# ATmega645P device description
Architecture: AVR8; Family: megaAVR
Registers are 8-bit, access not given, no defined reset value unless marked. A register's access mark holds for its fields unless they carry their own. Offsets are from the block's base; [hi:lo] are bit positions.

## JTAG — JTAG Interface
Instances: JTAG 0x00
0x51 OCDR — On-Chip Debug Related Register in I/O Memory
0x54 MCUSR — MCU Status Register
  [4] JTRF — JTAG Reset Flag
0x55 MCUCR — MCU Control Register
  [7] JTD — JTAG Interface Disable

## EXINT — External Interrupts
Instances: EXINT 0x00
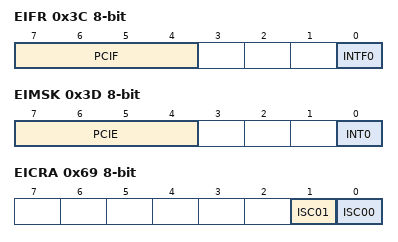
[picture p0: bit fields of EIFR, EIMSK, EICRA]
0x3C EIFR — External Interrupt Flag Register
  [7:4] PCIF — Pin Change Interrupt Flags
  [0] INTF0 — External Interrupt Flag 0
0x3D EIMSK — External Interrupt Mask Register
  [7:4] PCIE — Pin Change Interrupt Enables
  [0] INT0 — External Interrupt Request 0 Enable
0x69 EICRA — External Interrupt Control Register A
  [1] ISC01 — External Interrupt Sense Control 0 Bit 1
  [0] ISC00 — External Interrupt Sense Control 0 Bit 0
    0=Low Level of INTX; 1=Any Logical Change of INTX; 2=Falling Edge of INTX; 3=Rising Edge of INTX
0x6B PCMSK0 — Pin Change Mask Register 0
0x6C PCMSK1 — Pin Change Mask Register 1

## EEPROM
Instances: EEPROM 0x00
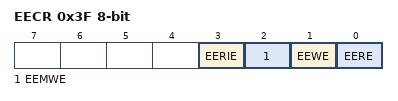
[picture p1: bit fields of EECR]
0x3F EECR — EEPROM Control Register
  [3] EERIE — EEPROM Ready Interrupt Enable
  [2] EEMWE — EEPROM Master Write Enable
  [1] EEWE — EEPROM Write Enable
  [0] EERE — EEPROM Read Enable
0x40 EEDR — EEPROM Data Register
0x41 EEAR 16-bit bits used 10:0 — EEPROM Read/Write Access Bytes

## PORTA — I/O Port
Instances: PORTA 0x00
0x20 PINA — Port A Input Pins
0x21 DDRA — Port A Data Direction Register
0x22 PORTA — Port A Data Register

## PORTB — I/O Port
Instances: PORTB 0x00
0x23 PINB — Port B Input Pins
0x24 DDRB — Port B Data Direction Register
0x25 PORTB — Port B Data Register

## PORTC — I/O Port
Instances: PORTC 0x00
0x26 PINC — Port C Input Pins
0x27 DDRC — Port C Data Direction Register
0x28 PORTC — Port C Data Register

## PORTD — I/O Port
Instances: PORTD 0x00
0x29 PIND — Port D Input Pins
0x2A DDRD — Port D Data Direction Register
0x2B PORTD — Port D Data Register

## PORTE — I/O Port
Instances: PORTE 0x00
0x2C PINE — Input Pins, Port E
0x2D DDRE — Data Direction Register, Port E
0x2E PORTE — Data Register, Port E

## PORTF — I/O Port
Instances: PORTF 0x00
0x2F PINF — Input Pins, Port F
0x30 DDRF — Data Direction Register, Port F
0x31 PORTF — Data Register, Port F

## PORTG — I/O Port
Instances: PORTG 0x00
0x32 PING bits used 5:0 — Port G Input Pins
0x33 DDRG bits used 4:0 — Port G Data Direction Register
0x34 PORTG bits used 4:0 — Port G Data Register

## TC0 (TC8 module) — Timer/Counter, 8-bit
Instances: TC0 0x00
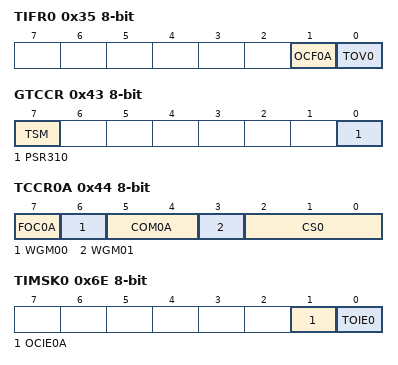
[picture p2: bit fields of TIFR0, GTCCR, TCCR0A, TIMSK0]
0x35 TIFR0 — Timer/Counter0 Interrupt Flag register
  [1] OCF0A — Timer/Counter0 Output Compare Flag 0
  [0] TOV0 — Timer/Counter0 Overflow Flag
0x43 GTCCR — General Timer/Control Register
  [7] TSM — Timer/Counter Synchronization Mode
  [0] PSR310 — Prescaler Reset Timer/Counter1 and Timer/Counter0
0x44 TCCR0A — Timer/Counter0 Control Register
  [7] FOC0A — Force Output Compare
  [6] WGM00 — Waveform Generation Mode 0
    0=Normal; 2=PWM, Phase Correct; 1=CTC; 3=Fast PWM
  [5:4] COM0A — Compare Match Output Modes
  [3] WGM01 — Waveform Generation Mode 1
  [2:0] CS0 — Clock Selects
    0=No Clock Source (Stopped); 1=Running, No Prescaling; 2=Running, CLK/8; 3=Running, CLK/64; 4=Running, CLK/256; 5=Running, CLK/1024; 6=Running, ExtClk Tx Falling Edge; 7=Running, ExtClk Tx Rising Edge
0x46 TCNT0 — Timer/Counter0
0x47 OCR0A — Timer/Counter0 Output Compare Register
0x6E TIMSK0 — Timer/Counter0 Interrupt Mask Register
  [1] OCIE0A — Timer/Counter0 Output Compare Match Interrupt Enable
  [0] TOIE0 — Timer/Counter0 Overflow Interrupt Enable

## TC2 (TC8_ASYNC module) — Timer/Counter, 8-bit Async
Instances: TC2 0x00
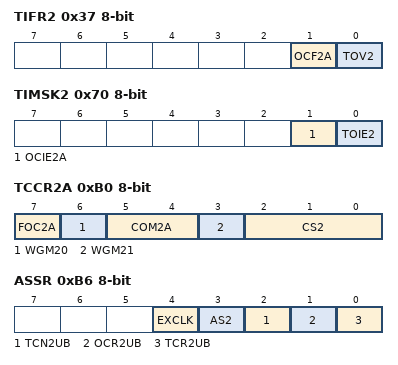
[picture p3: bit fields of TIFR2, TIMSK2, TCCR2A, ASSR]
0x37 TIFR2 — Timer/Counter2 Interrupt Flag Register
  [1] OCF2A — Timer/Counter2 Output Compare Flag 2
  [0] TOV2 — Timer/Counter2 Overflow Flag
0x43 GTCCR — General Timer/Counter Control Register
  [1] PSR2 — Prescaler Reset Timer/Counter2
0x70 TIMSK2 — Timer/Counter2 Interrupt Mask register
  [1] OCIE2A — Timer/Counter2 Output Compare Match Interrupt Enable
  [0] TOIE2 — Timer/Counter2 Overflow Interrupt Enable
0xB0 TCCR2A — Timer/Counter2 Control Register
  [7] FOC2A — Force Output Compare A
  [6] WGM20 — Waveform Generation Mode
    0=Normal; 2=PWM, Phase Correct; 1=CTC; 3=Fast PWM
  [5:4] COM2A — Compare Output Mode bits
  [3] WGM21 — Waveform Generation Mode
  [2:0] CS2 — Clock Select bits
    0=No Clock Source (Stopped); 1=Running, No Prescaling; 2=Running, CLK/8; 3=Running, CLK/32; 4=Running, CLK/64; 5=Running, CLK/128; 6=Running, CLK/256; 7=Running, CLK/1024
0xB2 TCNT2 — Timer/Counter2
0xB3 OCR2A — Timer/Counter2 Output Compare Register
0xB6 ASSR — Asynchronous Status Register
  [4] EXCLK — Enable External Clock Interrupt
  [3] AS2 — AS2: Asynchronous Timer/Counter2
  [2] TCN2UB — TCN2UB: Timer/Counter2 Update Busy
  [1] OCR2UB — Output Compare Register2 Update Busy
  [0] TCR2UB — TCR2UB: Timer/Counter Control Register2 Update Busy

## TC1 (TC16 module) — Timer/Counter, 16-bit
Instances: TC1 0x00
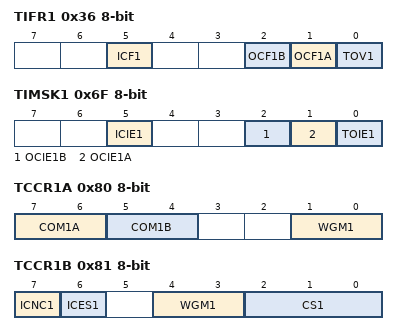
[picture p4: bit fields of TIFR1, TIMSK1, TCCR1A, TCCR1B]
0x36 TIFR1 — Timer/Counter1 Interrupt Flag register
  [5] ICF1 — Input Capture Flag 1
  [2] OCF1B — Output Compare Flag 1B
  [1] OCF1A — Output Compare Flag 1A
  [0] TOV1 — Timer/Counter1 Overflow Flag
0x6F TIMSK1 — Timer/Counter1 Interrupt Mask Register
  [5] ICIE1 — Timer/Counter1 Input Capture Interrupt Enable
  [2] OCIE1B — Timer/Counter1 Output Compare B Match Interrupt Enable
  [1] OCIE1A — Timer/Counter1 Output Compare A Match Interrupt Enable
  [0] TOIE1 — Timer/Counter1 Overflow Interrupt Enable
0x80 TCCR1A — Timer/Counter1 Control Register A
  [7:6] COM1A — Compare Output Mode 1A, bits
  [5:4] COM1B — Compare Output Mode 1B, bits
  [1:0] WGM1 — Waveform Generation Mode
0x81 TCCR1B — Timer/Counter1 Control Register B
  [7] ICNC1 — Input Capture 1 Noise Canceler
  [6] ICES1 — Input Capture 1 Edge Select
  [4:3] WGM1 (bit 2 of the value upward) — Waveform Generation Mode
  [2:0] CS1 — Prescaler source of Timer/Counter 1
    0=No Clock Source (Stopped); 1=Running, No Prescaling; 2=Running, CLK/8; 3=Running, CLK/64; 4=Running, CLK/256; 5=Running, CLK/1024; 6=Running, ExtClk Tx Falling Edge; 7=Running, ExtClk Tx Rising Edge
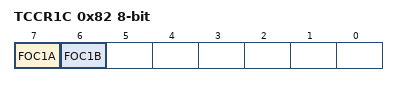
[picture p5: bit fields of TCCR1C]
0x82 TCCR1C — Timer/Counter 1 Control Register C
  [7] FOC1A — Force Output Compare 1A
  [6] FOC1B — Force Output Compare 1B
0x84 TCNT1 16-bit — Timer/Counter1 Bytes
0x86 ICR1 16-bit — Timer/Counter1 Input Capture Register Bytes
0x88 OCR1A 16-bit — Timer/Counter1 Output Compare Register A Bytes
0x8A OCR1B 16-bit — Timer/Counter1 Output Compare Register B Bytes

## WDT — Watchdog Timer
Instances: WDT 0x00
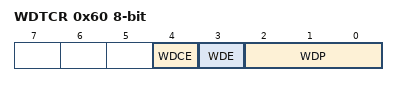
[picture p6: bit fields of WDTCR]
0x60 WDTCR — Watchdog Timer Control Register
  [4] WDCE — Watchdog Change Enable
  [3] WDE — Watch Dog Enable
  [2:0] WDP — Watch Dog Timer Prescaler bits
    0=Oscillator Cycles 16K; 1=Oscillator Cycles 32K; 2=Oscillator Cycles 64K; 3=Oscillator Cycles 128K; 4=Oscillator Cycles 256K; 5=Oscillator Cycles 512K; 6=Oscillator Cycles 1024K; 7=Oscillator Cycles 2048K

## BOOT_LOAD — Bootloader
Instances: BOOT_LOAD 0x00
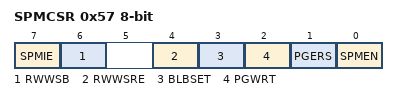
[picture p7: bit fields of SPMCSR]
0x57 SPMCSR — Store Program Memory Control Register
  [7] SPMIE — SPM Interrupt Enable
  [6] RWWSB — Read While Write Section Busy
  [4] RWWSRE — Read While Write section read enable
  [3] BLBSET — Boot Lock Bit Set
  [2] PGWRT — Page Write
  [1] PGERS — Page Erase
  [0] SPMEN — Store Program Memory Enable

## USART0 — USART
Instances: USART0 0x00
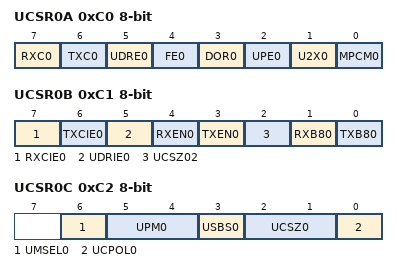
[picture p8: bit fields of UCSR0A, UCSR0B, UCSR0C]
0xC0 UCSR0A — USART Control and Status Register A
  [7] RXC0 — USART Receive Complete
  [6] TXC0 — USART Transmit Complete
  [5] UDRE0 — USART Data Register Empty
  [4] FE0 — Framing Error
  [3] DOR0 — Data OverRun
  [2] UPE0 — USART Parity Error
  [1] U2X0 — Double the USART Transmission Speed
  [0] MPCM0 — Multi-processor Communication Mode
0xC1 UCSR0B — USART Control and Status Register B
  [7] RXCIE0 — RX Complete Interrupt Enable
  [6] TXCIE0 — TX Complete Interrupt Enable
  [5] UDRIE0 — USART Data Register Empty Interrupt Enable
  [4] RXEN0 — Receiver Enable
  [3] TXEN0 — Transmitter Enable
  [2] UCSZ02 — Character Size
  [1] RXB80 — Receive Data Bit 8
  [0] TXB80 — Transmit Data Bit 8
0xC2 UCSR0C — USART Control and Status Register C
  [6] UMSEL0 — USART Mode Select
    0=Asynchronous Operation; 1=Synchronous Operation
  [5:4] UPM0 — Parity Mode Bits
    0=Disabled; 2=Enabled, Even Parity; 3=Enabled, Odd Parity
  [3] USBS0 — Stop Bit Select
    0=1-bit; 1=2-bit
  [2:1] UCSZ0 — Character Size
  [0] UCPOL0 — Clock Polarity
0xC4 UBRR0 16-bit bits used 11:0 — USART Baud Rate Register Bytes
0xC6 UDR0 — USART I/O Data Register
